# ESP32-C5-LP register map
Vendor: ESPRESSIF SYSTEMS (SHANGHAI) CO., LTD.; Series: ESP32 C-Series; File version: 1
32-bit RISC-V MCU
CPU: RV32IMAC r0p0, little endian, no MPU, no FPU, 0 interrupt priority bits
Address unit: 32 bits
Registers are 32-bit, read-write, reset 0x0 unless marked. A register's access mark holds for its fields unless they carry their own. Offsets are from the block's base; lines under a group give offsets from that group; [hi:lo] are bit positions; {n}, {i} and the like mark numbered series; 'fields as' and 'values as' point back to an identical list; <NAME> marks a mode.

## Memory map
0x600B0400 LP_CLKRST size 0x34 — LP_CLKRST Peripheral
0x600B0C00 LP_TIMER size 0x4C — Low-power Timer
0x600B1000 LP_AON size 0x80 — LP_AON Peripheral
0x600B1400 LP_UART size 0x84 — Low-power UART (Universal Asynchronous Receiver-Transmitter) Controller
0x600B1800 LP_I2C0 size 0x88 — Low-power I2C (Inter-Integrated Circuit) Controller 0
0x600B1C00 LP_WDT size 0x38 — Low-power Watchdog Timer
0x600B2400 LP_I2C_ANA_MST size 0x1C — LP_I2C_ANA_MST Peripheral
0x600B2800 LPPERI size 0x30 — LPPERI Peripheral
0x600B2C00 LP_ANA size 0x34 — LP_ANA Peripheral
0x600B3400 LP_TEE size 0x10 — Low-power Trusted Execution Environment
0x600B3800 LP_APM0 size 0x64 — LP_APM0 Peripheral
0x600B4000 LP_IO_MUX size 0x24 — Low-power Input/Output Multiplexer
0x600B4400 LP_IO size 0x74 — LP_IO Peripheral

## Interrupts
0 LP_IO_INT (LP_IO)
1 LP_I2C_INT (LP_I2C0)
2 LP_UART_INT (LP_UART)
3 LP_TIMER_INT (LP_TIMER)

## LP_ANA — LP_ANA Peripheral
Base 0x600B2C00
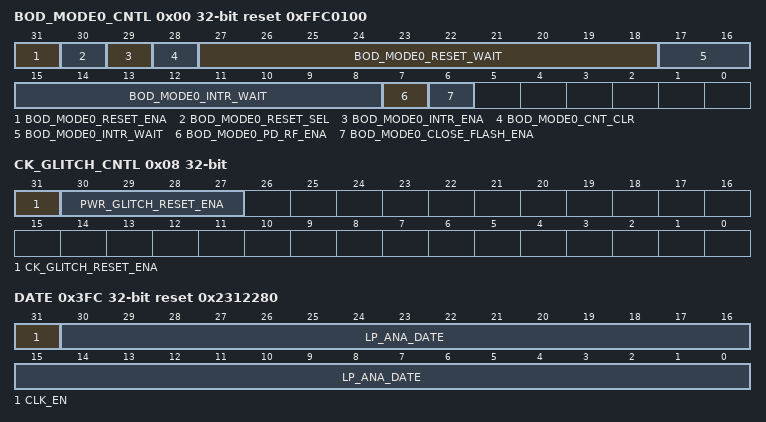
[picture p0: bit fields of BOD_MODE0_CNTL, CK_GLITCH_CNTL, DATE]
0x00 BOD_MODE0_CNTL reset 0xFFC0100 — Configure brownout mode0
  [31] BOD_MODE0_RESET_ENA — enable brownout reset or not 1: enable 0: disable
  [30] BOD_MODE0_RESET_SEL — select brownout reset level 1: system reset 0: chip reset
  [29] BOD_MODE0_INTR_ENA — enable brownout interrupt or not 1: enable 0: disable
  [28] BOD_MODE0_CNT_CLR — clear brownout count or not 1: clear 0: no operation
  [27:18] BOD_MODE0_RESET_WAIT — set the undervoltage hold time for triggering brownout reset
  [17:8] BOD_MODE0_INTR_WAIT — set the undervoltage hold time for triggering brownout interrupt
  [7] BOD_MODE0_PD_RF_ENA — enable power down RF when brownout interrupt or not 1:enable 0:disable
  [6] BOD_MODE0_CLOSE_FLASH_ENA — enable suspend spi when brownout interrupt or not 1:enable 0:disable
0x04 BOD_MODE1_CNTL — Configure brownout mode1
  [31] BOD_MODE1_RESET_ENA — enable brownout mode1 reset or not 1: enable 0: disable
0x08 CK_GLITCH_CNTL — Configure power glitch
  [31] CK_GLITCH_RESET_ENA — reserved
  [30:27] PWR_GLITCH_RESET_ENA — enable powerglitch or not
0x0C FIB_ENABLE reset 0xFFFFFFFF — configure FIB REG
  [31:0] ANA_FIB_ENA — configure analog fib by software
0x10 INT_RAW — interrpt raw register
  [31] BOD_MODE0_INT_RAW — brownout mode0 interrupt raw register
0x14 INT_ST ro — interrpt status register
  [31] BOD_MODE0_INT_ST — brownout mode0 interrupt status register
0x18 INT_ENA — interrpt enable register
  [31] BOD_MODE0_INT_ENA — brownout mode0 interrupt enable register
0x1C INT_CLR wo — interrpt clear register
  [31] BOD_MODE0_INT_CLR — brownout mode0 interrupt clear register
0x20 LP_INT_RAW — lp interrupt raw register
  [31] BOD_MODE0_LP_INT_RAW — brownout mode0 lp interrupt raw register
0x24 LP_INT_ST ro — lp interrupt status register
  [31] BOD_MODE0_LP_INT_ST — brownout mode0 lp interrupt status register
0x28 LP_INT_ENA — lp interrupt enable register
  [31] BOD_MODE0_LP_INT_ENA — brownout mode0 lp interrupt enable register
0x2C LP_INT_CLR wo — lp interrupt clear register
  [31] BOD_MODE0_LP_INT_CLR — brownout mode0 lp interrupt clear register
0x3FC DATE reset 0x2312280 — version register
  [31] CLK_EN — reserved
  [30:0] LP_ANA_DATE — version register

## Licence text in the file
Copyright 2025 Espressif Systems (Shanghai) PTE LTD Licensed under the Apache License, Version 2.0 (the "License"); you may not use this file except in compliance with the License. You may obtain a copy of the License at http://www.apache.org/licenses/LICENSE-2.0 Unless required by applicable law or agreed to in writing, software distributed under the License is distributed on an "AS IS" BASIS, WITHOUT WARRANTIES OR CONDITIONS OF ANY KIND, either express or implied. See the License for the specific language governing permissions and limitations under the License.
